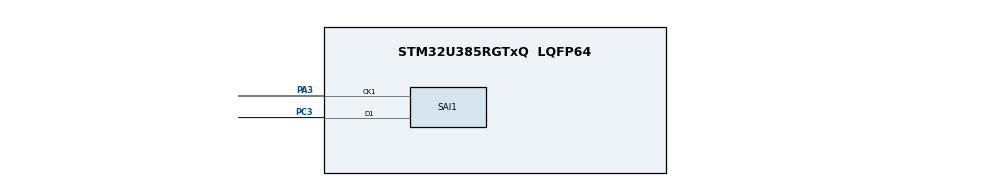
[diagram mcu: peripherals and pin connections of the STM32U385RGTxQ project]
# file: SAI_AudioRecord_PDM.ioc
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CORTEX_M33_NS.userName=CORTEX_M33
GPDMA1.CIRCULARMODE_GPDMACH0=ENABLE
GPDMA1.DESTINC_GPDMACH0=DMA_DINC_INCREMENTED
GPDMA1.IPHANDLE_GPDMACH0-SIMPLEREQUEST_GPDMACH0=__NULL
GPDMA1.LINKALLOCATEDPORT_CIRCULAR_GPDMACH0=DMA_LINK_ALLOCATED_PORT1
GPDMA1.PRIORITY_LL_CIRCULAR_GPDMACH0=DMA_LOW_PRIORITY_HIGH_WEIGHT
GPDMA1.REQUEST_GPDMACH0=GPDMA1_REQUEST_SAI1_A
GPDMA1.TRANSFERALLOCATEDPORTDEST_GPDMACH0=DMA_DEST_ALLOCATED_PORT1
Mcu.Family=STM32U3
Mcu.Name=STM32U385RGTxQ
Mcu.Package=LQFP64
NVIC.GPDMA1_Channel0_IRQn=true\:0\:0\:false\:false\:true\:false\:true\:true
NVIC.PriorityGroup=NVIC_PRIORITYGROUP_4
NVIC.SAI1_IRQn=true\:0\:0\:false\:false\:true\:true\:true\:true
PA3.GPIO_Speed=GPIO_SPEED_FREQ_HIGH
PA3.Mode=PDM_Master_Mode_CK1
PA3.Signal=SAI1_CK1
PC3.GPIO_Speed=GPIO_SPEED_FREQ_HIGH
PC3.Mode=PDM_Master_Mode_CK1
PC3.Signal=SAI1_D1
ProjectManager.HeapSize=0x200
ProjectManager.StackSize=0x400
ProjectManager.TargetToolchain=EWARM V9.20
RCC.ADCFreq_Value=96000000
RCC.AHBFreq_Value=96000000
RCC.APB1Freq_Value=96000000
RCC.APB1TimFreq_Value=96000000
RCC.APB2Freq_Value=96000000
RCC.APB2TimFreq_Value=96000000
RCC.APB3Freq_Value=96000000
RCC.CortexFreq_Value=12000000
RCC.HCLKFreq_Value=96000000
RCC.HSE_VALUE=16000000
RCC.HSI48_VALUE=48000000
RCC.HSI_VALUE=16000000
RCC.LSE_VALUE=32768
RCC.LSIDIV_VALUE=32000
RCC.MSIKDIV=RCC_MSI_DIV2
RCC.MSISDIV=RCC_MSI_DIV1
RCC.MSI_VALUE=96000000
RCC.SYSCLKFreq_VALUE=96000000
RCC.USBFreq_Value=96000000
SAI1.Activation=ENABLE
SAI1.AudioFrequency-PDM_Master_Mode_CK1=SAI_AUDIO_FREQUENCY_MCKDIV
SAI1.ErrorAudioFreq-PDM_Master_Mode_CK1=-2.34 %
SAI1.FIFOThreshold-PDM_Master_Mode_CK1=SAI_FIFOTHRESHOLD_1QF
SAI1.FSPolarity-PDM_Master_Mode_CK1=SAI_FS_ACTIVE_HIGH
SAI1.FirstBit-PDM_Master_Mode_CK1=SAI_FIRSTBIT_LSB
SAI1.FrameLength-PDM_Master_Mode_CK1=16
SAI1.Instance-PDM_Master_Mode_CK1=SAI$Index_Block_A
SAI1.MckOutput-PDM_Master_Mode_CK1=SAI_MCK_OUTPUT_DISABLE
SAI1.Mckdiv-PDM_Master_Mode_CK1=24
SAI1.NoDivider-PDM_Master_Mode_CK1=SAI_MASTERDIVIDER_DISABLE
SAI1.OutputDrive-PDM_Master_Mode_CK1=SAI_OUTPUTDRIVE_ENABLE
SAI1.RealAudioFreq-PDM_Master_Mode_CK1=0 Hz
SAI1.SlotActive-PDM_Master_Mode_CK1=0x0000FFFF
SAI1.SlotNumber-PDM_Master_Mode_CK1=2
SAI1.VirtualMode-PDM_Master_Mode_CK1=VM_MASTER
SAI1.VirtualProtocol-PDM_Master_Mode_CK1=VM_PDM_PROTOCOL
SAI1.VirtualSlotActive-PDM_Master_Mode_CK1=SAI_SLOTACTIVE_ALL
VP_GPDMA1_VS_GPDMACH0.Mode=SIMPLEREQUEST_GPDMACH0
VP_ICACHE_VS_ICACHE.Mode=DirectMappedCache
VP_PWR_VS_DBSignals.Mode=DisableDeadBatterySignals
VP_PWR_VS_LPOM.Mode=PowerOptimisation
VP_PWR_VS_SECSignals.Mode=Security/Privilege
board=custom

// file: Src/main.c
/* USER CODE BEGIN Header */
/**
  ******************************************************************************
  * @file           : main.c
  * @brief          : Main program body
  ******************************************************************************
  * @attention
  *
  * Copyright (c) 2024 STMicroelectronics.
  * All rights reserved.
  *
  * This software is licensed under terms that can be found in the LICENSE file
  * in the root directory of this software component.
  * If no LICENSE file comes with this software, it is provided AS-IS.
  *
  ******************************************************************************
  */
/* USER CODE END Header */
#include "main.h"

/* USER CODE BEGIN Includes */
#include "pdm2pcm_glo.h"
#include "stm32u3xx_nucleo.h"
/* USER CODE END Includes */

SAI_HandleTypeDef hsai_BlockA1;
DMA_NodeTypeDef Node_GPDMA1_Channel0;
DMA_QListTypeDef List_GPDMA1_Channel0;
DMA_HandleTypeDef handle_GPDMA1_Channel0;

/* USER CODE BEGIN PV */
static uint8_t  PdmBuffer[10240U]; /* 40ms */
static uint16_t PcmBuffer[64000U]; /* 2s */

static __IO uint32_t PdmHalfBufferCplt;
static __IO uint32_t PdmBufferCplt;
static uint32_t Loop;

static uint32_t PcmBufferPtr;
/* USER CODE END PV */

void SystemClock_Config(void);
static void MX_GPIO_Init(void);
static void MX_GPDMA1_Init(void);
static void MX_ICACHE_Init(void);
static void MX_SAI1_Init(void);

int main(void)
{

  /* USER CODE BEGIN 1 */
  PDM_Filter_Handler_t  PDM_FilterHandler[2];
  PDM_Filter_Config_t   PDM_FilterConfig[2];
  uint32_t i;
  /* USER CODE END 1 */

  /* MCU Configuration--------------------------------------------------------*/

  /* Reset of all peripherals, Initializes the Flash interface and the Systick. */
  HAL_Init();

  /* Configure the system clock */
  SystemClock_Config();

  /* USER CODE BEGIN SysInit */
  if (BSP_ERROR_NONE != BSP_LED_Init(LED_GREEN))
  {
    Error_Handler();
  }
  /* USER CODE END SysInit */

  /* Initialize all configured peripherals */
  MX_GPIO_Init();
  MX_GPDMA1_Init();
  MX_ICACHE_Init();
  MX_SAI1_Init();
  /* USER CODE BEGIN 2 */
  /* Enable CRC peripheral to unlock the PDM library */
  __HAL_RCC_CRC_CLK_ENABLE();

  /* Init and configure PDM filters */
  for (i = 0; i < 2; i++)
  {
    PDM_FilterHandler[i].bit_order  = PDM_FILTER_BIT_ORDER_MSB;
    PDM_FilterHandler[i].endianness = PDM_FILTER_ENDIANNESS_LE;
    PDM_FilterHandler[i].high_pass_tap = 2122358088;
    PDM_FilterHandler[i].out_ptr_channels = 2;
    PDM_FilterHandler[i].in_ptr_channels  = 2;
    if (0 != PDM_Filter_Init((PDM_Filter_Handler_t *)(&PDM_FilterHandler[i])))
    {
      Error_Handler();
    }
  }
  for (i = 0; i < 2; i++)
  {
    PDM_FilterConfig[i].mic_gain = 24;
    PDM_FilterConfig[i].output_samples_number = 320;
    PDM_FilterConfig[i].decimation_factor = PDM_FILTER_DEC_FACTOR_64;
    if (0 != PDM_Filter_setConfig((PDM_Filter_Handler_t *)&PDM_FilterHandler[i], &PDM_FilterConfig[i]))
    {
      Error_Handler();
    }
  }

  /* Start PDM record */
  PdmHalfBufferCplt = 0;
  PdmBufferCplt = 0;
  PcmBufferPtr = 0;
  Loop = 0;
  if (HAL_OK != HAL_SAI_Receive_DMA(&hsai_BlockA1, PdmBuffer, 10240U))
  {
    Error_Handler();
  }
  /* USER CODE END 2 */

  /* Infinite loop */
  while (1)
  {

    /* USER CODE BEGIN 3 */
    if (PdmHalfBufferCplt == 1)
    {
      /* Store values on PCM buffer */
      if (0 != PDM_Filter(&PdmBuffer[0], &PcmBuffer[PcmBufferPtr], &PDM_FilterHandler[0]))
      {
        Error_Handler();
      }
      if (0 != PDM_Filter(&PdmBuffer[1], &PcmBuffer[PcmBufferPtr + 1], &PDM_FilterHandler[1]))
      {
        Error_Handler();
      }
      PcmBufferPtr += 640;

      /* Reset half buffer complete flag */
      PdmHalfBufferCplt = 0;
      if (PdmBufferCplt == 1)
      {
        Error_Handler();
      }
    }
    if (PdmBufferCplt == 1)
    {
      /* Store values on PCM buffer */
      /* Store values on PCM buffer */
      if (0 != PDM_Filter(&PdmBuffer[5120], &PcmBuffer[PcmBufferPtr], &PDM_FilterHandler[0]))
      {
        Error_Handler();
      }
      if (0 != PDM_Filter(&PdmBuffer[5121], &PcmBuffer[PcmBufferPtr + 1], &PDM_FilterHandler[1]))
      {
        Error_Handler();
      }
      PcmBufferPtr += 640;
      if(PcmBufferPtr >= 64000)
      {
        PcmBufferPtr = 0;
        Loop++;
        if (Loop == 5U)
        {
          /* Stop PDM record */
          if (HAL_OK != HAL_SAI_Abort(&hsai_BlockA1))
          {
            Error_Handler();
          }

          if (BSP_ERROR_NONE != BSP_LED_On(LED_GREEN))
          {
            Error_Handler();
          }
        }
      }

      /* Reset buffer complete flag */
      PdmBufferCplt = 0;
      if (PdmHalfBufferCplt == 1)
      {
        Error_Handler();
      }
    }
  }
  /* USER CODE END 3 */
}

void SystemClock_Config(void)
{
  RCC_OscInitTypeDef RCC_OscInitStruct = {0};
  RCC_ClkInitTypeDef RCC_ClkInitStruct = {0};

  /** Enable Epod Booster
  */
  if (HAL_RCCEx_EpodBoosterClkConfig(RCC_EPODBOOSTER_SOURCE_MSIS, RCC_EPODBOOSTER_DIV1) != HAL_OK)
  {
    Error_Handler();
  }

  if (HAL_PWREx_EnableEpodBooster() != HAL_OK)
  {
    Error_Handler();
  }

  /** Configure the main internal regulator output voltage
  */
  if (HAL_PWREx_ControlVoltageScaling(PWR_REGULATOR_VOLTAGE_SCALE1) != HAL_OK)
  {
    Error_Handler();
  }

  /** Set Flash latency before increasing MSIS
  */
  __HAL_FLASH_SET_LATENCY(FLASH_LATENCY_2);

  /** Initializes the CPU, AHB and APB buses clocks
  */
  RCC_OscInitStruct.OscillatorType = RCC_OSCILLATORTYPE_MSIS|RCC_OSCILLATORTYPE_MSIK;
  RCC_OscInitStruct.MSISState = RCC_MSI_ON;
  RCC_OscInitStruct.MSISSource = RCC_MSI_RC0;
  RCC_OscInitStruct.MSISDiv = RCC_MSI_DIV1;
  RCC_OscInitStruct.MSIKState = RCC_MSI_ON;
  RCC_OscInitStruct.MSIKSource = RCC_MSI_RC0;
  RCC_OscInitStruct.MSIKDiv = RCC_MSI_DIV2;

  if (HAL_RCC_OscConfig(&RCC_OscInitStruct) != HAL_OK)
  {
    Error_Handler();
  }

  /** Initializes the CPU, AHB and APB buses clocks
  */
  RCC_ClkInitStruct.ClockType = RCC_CLOCKTYPE_HCLK|RCC_CLOCKTYPE_SYSCLK
                              |RCC_CLOCKTYPE_PCLK1|RCC_CLOCKTYPE_PCLK2
                              |RCC_CLOCKTYPE_PCLK3;
  RCC_ClkInitStruct.SYSCLKSource = RCC_SYSCLKSOURCE_MSIS;
  RCC_ClkInitStruct.AHBCLKDivider = RCC_SYSCLK_DIV1;
  RCC_ClkInitStruct.APB1CLKDivider = RCC_HCLK_DIV1;
  RCC_ClkInitStruct.APB2CLKDivider = RCC_HCLK_DIV1;
  RCC_ClkInitStruct.APB3CLKDivider = RCC_HCLK_DIV1;

  if (HAL_RCC_ClockConfig(&RCC_ClkInitStruct, FLASH_LATENCY_2) != HAL_OK)
  {
    Error_Handler();
  }
}

static void MX_GPDMA1_Init(void)
{

  /* Peripheral clock enable */
  __HAL_RCC_GPDMA1_CLK_ENABLE();

  /* GPDMA1 interrupt Init */
    HAL_NVIC_SetPriority(GPDMA1_Channel0_IRQn, 0, 0);
    HAL_NVIC_EnableIRQ(GPDMA1_Channel0_IRQn);

}

static void MX_ICACHE_Init(void)
{

  /** Enable instruction cache in 1-way (direct mapped cache)
  */
  if (HAL_ICACHE_ConfigAssociativityMode(ICACHE_1WAY) != HAL_OK)
  {
    Error_Handler();
  }
  if (HAL_ICACHE_Enable() != HAL_OK)
  {
    Error_Handler();
  }

}

static void MX_SAI1_Init(void)
{

  hsai_BlockA1.Instance = SAI1_Block_A;
  hsai_BlockA1.Init.Protocol = SAI_FREE_PROTOCOL;
  hsai_BlockA1.Init.AudioMode = SAI_MODEMASTER_RX;
  hsai_BlockA1.Init.DataSize = SAI_DATASIZE_8;
  hsai_BlockA1.Init.FirstBit = SAI_FIRSTBIT_LSB;
  hsai_BlockA1.Init.ClockStrobing = SAI_CLOCKSTROBING_FALLINGEDGE;
  hsai_BlockA1.Init.Synchro = SAI_ASYNCHRONOUS;
  hsai_BlockA1.Init.OutputDrive = SAI_OUTPUTDRIVE_ENABLE;
  hsai_BlockA1.Init.NoDivider = SAI_MASTERDIVIDER_DISABLE;
  hsai_BlockA1.Init.FIFOThreshold = SAI_FIFOTHRESHOLD_1QF;
  hsai_BlockA1.Init.AudioFrequency = SAI_AUDIO_FREQUENCY_MCKDIV;
  hsai_BlockA1.Init.Mckdiv = 24;
  hsai_BlockA1.Init.MckOutput = SAI_MCK_OUTPUT_DISABLE;
  hsai_BlockA1.Init.MonoStereoMode = SAI_STEREOMODE;
  hsai_BlockA1.Init.CompandingMode = SAI_NOCOMPANDING;
  hsai_BlockA1.Init.PdmInit.Activation = ENABLE;
  hsai_BlockA1.Init.PdmInit.MicPairsNbr = 1;
  hsai_BlockA1.Init.PdmInit.ClockEnable = SAI_PDM_CLOCK1_ENABLE;
  hsai_BlockA1.FrameInit.FrameLength = 16;
  hsai_BlockA1.FrameInit.ActiveFrameLength = 1;
  hsai_BlockA1.FrameInit.FSDefinition = SAI_FS_STARTFRAME;
  hsai_BlockA1.FrameInit.FSPolarity = SAI_FS_ACTIVE_HIGH;
  hsai_BlockA1.FrameInit.FSOffset = SAI_FS_FIRSTBIT;
  hsai_BlockA1.SlotInit.FirstBitOffset = 0;
  hsai_BlockA1.SlotInit.SlotSize = SAI_SLOTSIZE_DATASIZE;
  hsai_BlockA1.SlotInit.SlotNumber = 2;
  hsai_BlockA1.SlotInit.SlotActive = 0x0000FFFF;
  if (HAL_SAI_Init(&hsai_BlockA1) != HAL_OK)
  {
    Error_Handler();
  }

}

static void MX_GPIO_Init(void)
{

  /* GPIO Ports Clock Enable */
  __HAL_RCC_GPIOC_CLK_ENABLE();
  __HAL_RCC_GPIOA_CLK_ENABLE();

}

/* USER CODE BEGIN 4 */
/**
  * @brief Rx Transfer completed callback.
  * @param  hsai pointer to a SAI_HandleTypeDef structure that contains
  *              the configuration information for SAI module.
  * @retval None
  */
void HAL_SAI_RxCpltCallback(SAI_HandleTypeDef *hsai)
{
  if (hsai->Instance == hsai_BlockA1.Instance)
  {
    PdmBufferCplt++;
  }
}

/**
  * @brief Rx Transfer half completed callback.
  * @param  hsai pointer to a SAI_HandleTypeDef structure that contains
  *              the configuration information for SAI module.
  * @retval None
  */
void HAL_SAI_RxHalfCpltCallback(SAI_HandleTypeDef *hsai)
{
  if (hsai->Instance == hsai_BlockA1.Instance)
  {
    PdmHalfBufferCplt++;
  }
}
/* USER CODE END 4 */

void Error_Handler(void)
{
  /* USER CODE BEGIN Error_Handler_Debug */
  /* User can add his own implementation to report the HAL error return state */
  while (1)
  {
    /* Toggle green led for error */
    (void) BSP_LED_Toggle(LED_GREEN);
    HAL_Delay(500);
  }
  /* USER CODE END Error_Handler_Debug */
}
